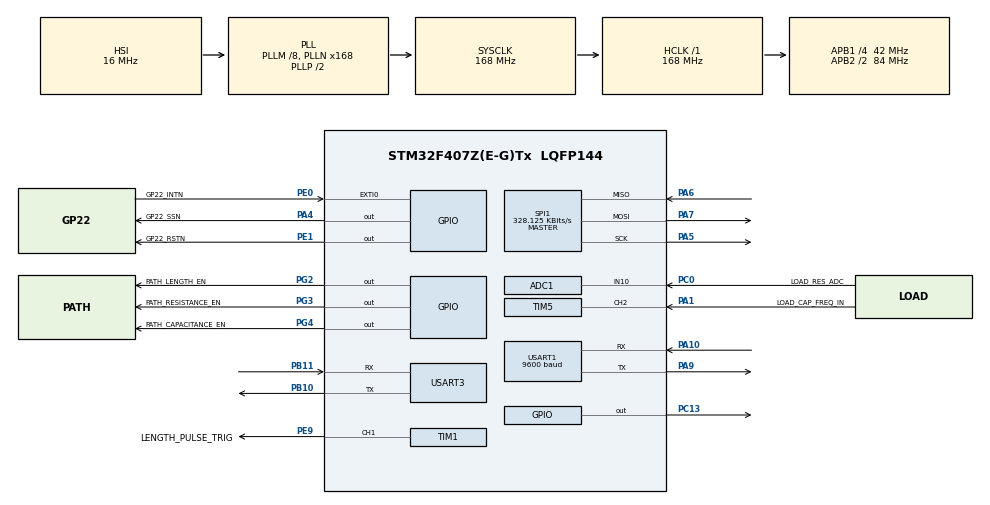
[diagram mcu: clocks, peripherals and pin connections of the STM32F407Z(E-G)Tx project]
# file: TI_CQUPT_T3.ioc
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ADC1.Channel-4\#ChannelRegularConversion=ADC_CHANNEL_10
ADC1.NbrOfConversion=1
ADC1.NbrOfConversionFlag=1
ADC1.Rank-4\#ChannelRegularConversion=1
ADC1.SamplingTime-4\#ChannelRegularConversion=ADC_SAMPLETIME_84CYCLES
ADC1.master=1
Mcu.Family=STM32F4
Mcu.Name=STM32F407Z(E-G)Tx
Mcu.Package=LQFP144
NVIC.EXTI0_IRQn=true\:2\:0\:true\:false\:true\:true\:true\:true
NVIC.PriorityGroup=NVIC_PRIORITYGROUP_4
NVIC.TIM5_IRQn=true\:0\:0\:false\:false\:true\:true\:true\:true
NVIC.USART1_IRQn=true\:0\:0\:false\:false\:true\:true\:true\:true
PA1.GPIO_Label=LOAD_CAP_FREQ_IN
PA1.Signal=S_TIM5_CH2
PA10.Mode=Asynchronous
PA10.Signal=USART1_RX
PA13.Mode=Serial_Wire
PA13.Signal=SYS_JTMS-SWDIO
PA14.Mode=Serial_Wire
PA14.Signal=SYS_JTCK-SWCLK
PA4.GPIO_Label=GP22_SSN
PA4.GPIO_Speed=GPIO_SPEED_FREQ_HIGH
PA4.PinState=GPIO_PIN_SET
PA4.Signal=GPIO_Output
PA5.Mode=Full_Duplex_Master
PA5.Signal=SPI1_SCK
PA6.Mode=Full_Duplex_Master
PA6.Signal=SPI1_MISO
PA7.Mode=Full_Duplex_Master
PA7.Signal=SPI1_MOSI
PA9.Mode=Asynchronous
PA9.Signal=USART1_TX
PB10.Mode=Asynchronous
PB10.Signal=USART3_TX
PB11.Mode=Asynchronous
PB11.Signal=USART3_RX
PC0.GPIO_Label=LOAD_RES_ADC
PC0.Signal=ADCx_IN10
PC13-ANTI_TAMP.PinState=GPIO_PIN_RESET
PC13-ANTI_TAMP.Signal=GPIO_Output
PE0.GPIO_Label=GP22_INTN
PE0.GPIO_ModeDefaultEXTI=GPIO_MODE_IT_FALLING
PE0.GPIO_PuPd=GPIO_PULLUP
PE0.Signal=GPXTI0
PE1.GPIO_Label=GP22_RSTN
PE1.GPIO_Speed=GPIO_SPEED_FREQ_HIGH
PE1.PinState=GPIO_PIN_SET
PE1.Signal=GPIO_Output
PE9.GPIO_Label=LENGTH_PULSE_TRIG
PE9.GPIO_Speed=GPIO_SPEED_FREQ_VERY_HIGH
PE9.Signal=S_TIM1_CH1
PG2.GPIO_Label=PATH_LENGTH_EN
PG2.Signal=GPIO_Output
PG3.GPIO_Label=PATH_RESISTANCE_EN
PG3.Signal=GPIO_Output
PG4.GPIO_Label=PATH_CAPACITANCE_EN
PG4.Signal=GPIO_Output
PH0-OSC_IN.Mode=HSE-External-Oscillator
PH0-OSC_IN.Signal=RCC_OSC_IN
PH1-OSC_OUT.Mode=HSE-External-Oscillator
PH1-OSC_OUT.Signal=RCC_OSC_OUT
ProjectManager.HeapSize=0x200
ProjectManager.StackSize=0x400
ProjectManager.TargetToolchain=MDK-ARM V5.32
RCC.48MHZClocksFreq_Value=84000000
RCC.AHBFreq_Value=168000000
RCC.APB1CLKDivider=RCC_HCLK_DIV4
RCC.APB1Freq_Value=42000000
RCC.APB1TimFreq_Value=84000000
RCC.APB2CLKDivider=RCC_HCLK_DIV2
RCC.APB2Freq_Value=84000000
RCC.APB2TimFreq_Value=168000000
RCC.CortexFreq_Value=168000000
RCC.HCLKFreq_Value=168000000
RCC.HSE_VALUE=25000000
RCC.HSI_VALUE=16000000
RCC.LSE_VALUE=32768
RCC.PLLM=8
RCC.PLLN=168
RCC.SYSCLKFreq_VALUE=168000000
RCC.SYSCLKSource=RCC_SYSCLKSOURCE_PLLCLK
RCC.VCOOutputFreq_Value=336000000
SH.ADCx_IN10.0=ADC1_IN10,IN10
SH.S_TIM1_CH1.0=TIM1_CH1,PWM Generation1 CH1
SH.S_TIM5_CH2.0=TIM5_CH2,Input_Capture2_from_TI2
SPI1.BaudRatePrescaler=SPI_BAUDRATEPRESCALER_256
SPI1.CLKPhase=SPI_PHASE_2EDGE
SPI1.CalculateBaudRate=328.125 KBits/s
SPI1.Direction=SPI_DIRECTION_2LINES
SPI1.Mode=SPI_MODE_MASTER
SPI1.VirtualType=VM_MASTER
TIM1.Channel-PWM\ Generation1\ CH1=TIM_CHANNEL_1
TIM1.Period=168 - 1
TIM1.Pulse-PWM\ Generation1\ CH1=84
TIM5.Channel-Input_Capture2_from_TI2=TIM_CHANNEL_2
TIM5.ICFilter_CH2=2
TIM5.Prescaler=42 -1
USART1.BaudRate=9600
USART1.VirtualMode=VM_ASYNC
USART3.VirtualMode=VM_ASYNC
VP_TIM1_VS_ClockSourceINT.Mode=Internal
VP_TIM1_VS_OPM.Mode=OPM_bit
VP_TIM5_VS_ClockSourceINT.Mode=Internal
board=custom

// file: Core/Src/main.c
/* USER CODE BEGIN Header */
/**
 ******************************************************************************
 * @file           : main.c
 * @brief          : Main program body
 ******************************************************************************
 * @attention
 *
 * Copyright (c) 2026 STMicroelectronics.
 * All rights reserved.
 *
 * This software is licensed under terms that can be found in the LICENSE file
 * in the root directory of this software component.
 * If no LICENSE file comes with this software, it is provided AS-IS.
 *
 ******************************************************************************
 */
/* USER CODE END Header */
#include "main.h"
#include "adc.h"
#include "spi.h"
#include "tim.h"
#include "usart.h"
#include "gpio.h"

/* USER CODE BEGIN Includes */
#include "app_process.h"
#include "bsp_length.h"
#include "bsp_load.h"
#include "bsp_path.h"
/* USER CODE END Includes */

void SystemClock_Config(void);

int main(void)
{

  /* MCU Configuration--------------------------------------------------------*/

  /* Reset of all peripherals, Initializes the Flash interface and the Systick. */
  HAL_Init();

  /* Configure the system clock */
  SystemClock_Config();

  /* Initialize all configured peripherals */
  MX_GPIO_Init();
  MX_USART1_UART_Init();
  MX_USART3_UART_Init();
  MX_ADC1_Init();
  MX_TIM5_Init();
  MX_SPI1_Init();
  MX_TIM1_Init();
  /* USER CODE BEGIN 2 */
  bsp_path_init();
  bsp_load_init();
  HMI_Process_Init();
  /* USER CODE END 2 */

  /* Infinite loop */
  /* USER CODE BEGIN WHILE */
  while (1)
  {
    App_Main_Process_Poll();
    /* USER CODE END WHILE */

  }
}

void SystemClock_Config(void)
{
  RCC_OscInitTypeDef RCC_OscInitStruct = {0};
  RCC_ClkInitTypeDef RCC_ClkInitStruct = {0};

  /** Configure the main internal regulator output voltage
  */
  __HAL_RCC_PWR_CLK_ENABLE();
  __HAL_PWR_VOLTAGESCALING_CONFIG(PWR_REGULATOR_VOLTAGE_SCALE1);

  /** Initializes the RCC Oscillators according to the specified parameters
  * in the RCC_OscInitTypeDef structure.
  */
  RCC_OscInitStruct.OscillatorType = RCC_OSCILLATORTYPE_HSI;
  RCC_OscInitStruct.HSIState = RCC_HSI_ON;
  RCC_OscInitStruct.HSICalibrationValue = RCC_HSICALIBRATION_DEFAULT;
  RCC_OscInitStruct.PLL.PLLState = RCC_PLL_ON;
  RCC_OscInitStruct.PLL.PLLSource = RCC_PLLSOURCE_HSI;
  RCC_OscInitStruct.PLL.PLLM = 8;
  RCC_OscInitStruct.PLL.PLLN = 168;
  RCC_OscInitStruct.PLL.PLLP = RCC_PLLP_DIV2;
  RCC_OscInitStruct.PLL.PLLQ = 4;
  if (HAL_RCC_OscConfig(&RCC_OscInitStruct) != HAL_OK)
  {
    Error_Handler();
  }

  /** Initializes the CPU, AHB and APB buses clocks
  */
  RCC_ClkInitStruct.ClockType = RCC_CLOCKTYPE_HCLK|RCC_CLOCKTYPE_SYSCLK
                              |RCC_CLOCKTYPE_PCLK1|RCC_CLOCKTYPE_PCLK2;
  RCC_ClkInitStruct.SYSCLKSource = RCC_SYSCLKSOURCE_PLLCLK;
  RCC_ClkInitStruct.AHBCLKDivider = RCC_SYSCLK_DIV1;
  RCC_ClkInitStruct.APB1CLKDivider = RCC_HCLK_DIV4;
  RCC_ClkInitStruct.APB2CLKDivider = RCC_HCLK_DIV2;

  if (HAL_RCC_ClockConfig(&RCC_ClkInitStruct, FLASH_LATENCY_5) != HAL_OK)
  {
    Error_Handler();
  }
}

/* USER CODE BEGIN 4 */

void HAL_TIM_IC_CaptureCallback(TIM_HandleTypeDef *htim)
{
  /* ISR内只转发TIM5捕获事件，周期换算与日志均在主循环完成。 */
  bsp_load_on_tim_capture_irq(htim);
}

void HAL_GPIO_EXTI_Callback(uint16_t GPIO_Pin)
{
  /* PE0下降沿只发布GP22完成标志，不在中断中访问SPI。 */
  bsp_length_on_gp22_irq(GPIO_Pin);
}

/* USER CODE END 4 */

void Error_Handler(void)
{
  __disable_irq();
  while (1)
  {
  }
}
